VERSION ""

NS_ :

BS_:

BU_: VCU WheelSpeedSensor MotorController TempSensors BMS IMU

BO_ 256 WheelSpeed: 8 WheelSpeedSensor
 SG_ Speed_kmh : 0|16@1+ (0.1,0) [0|300] "km/h" VCU

BO_ 257 MotorRPM: 8 MotorController
 SG_ Motor_RPM : 0|16@1+ (1,0) [0|20000] "rpm" VCU

BO_ 258 MotorTemp: 8 TempSensors
 SG_ Motor_Temp_C : 0|16@1- (0.1,0) [-40|200] "degC" VCU

BO_ 259 CoolantTemp: 8 TempSensors
 SG_ Coolant_In_C : 0|16@1- (0.1,0) [-40|150] "degC" VCU
 SG_ Coolant_Out_C : 16|16@1- (0.1,0) [-40|150] "degC" VCU

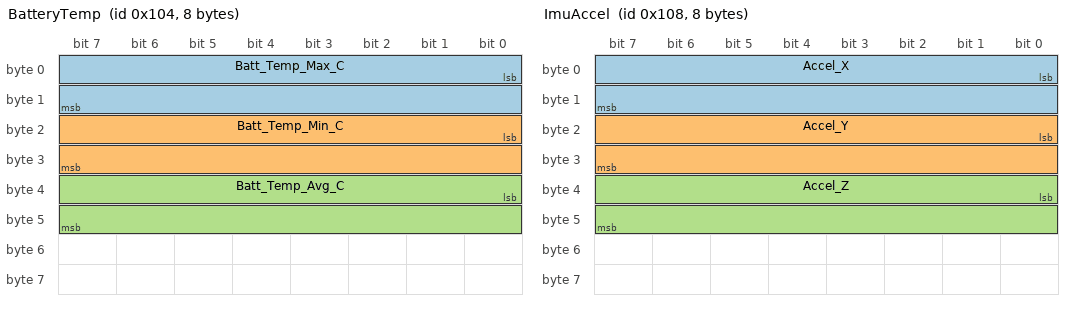
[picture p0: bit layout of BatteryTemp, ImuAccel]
BO_ 260 BatteryTemp: 8 BMS
 SG_ Batt_Temp_Max_C : 0|16@1- (0.1,0) [-40|100] "degC" VCU
 SG_ Batt_Temp_Min_C : 16|16@1- (0.1,0) [-40|100] "degC" VCU
 SG_ Batt_Temp_Avg_C : 32|16@1- (0.1,0) [-40|100] "degC" VCU

BO_ 261 BatteryVoltage: 8 BMS
 SG_ Pack_Voltage_V : 0|16@1+ (0.1,0) [0|500] "V" VCU

BO_ 262 BatteryCurrent: 8 BMS
 SG_ Pack_Current_A : 0|16@1- (0.1,0) [-500|500] "A" VCU

BO_ 263 InverterTemp: 8 MotorController
 SG_ Inverter_Temp_C : 0|16@1- (0.1,0) [-40|200] "degC" VCU

BO_ 264 ImuAccel: 8 IMU
 SG_ Accel_X : 0|16@1- (0.001,0) [-16|16] "g" VCU
 SG_ Accel_Y : 16|16@1- (0.001,0) [-16|16] "g" VCU
 SG_ Accel_Z : 32|16@1- (0.001,0) [-16|16] "g" VCU

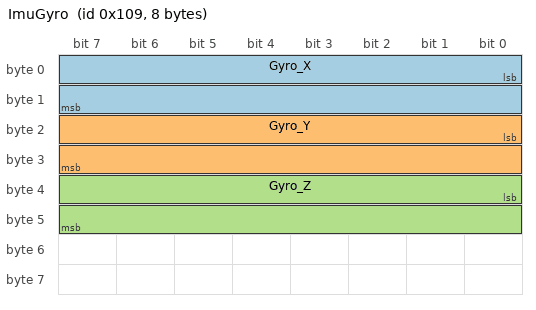
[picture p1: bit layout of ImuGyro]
BO_ 265 ImuGyro: 8 IMU
 SG_ Gyro_X : 0|16@1- (0.01,0) [-2000|2000] "deg/s" VCU
 SG_ Gyro_Y : 16|16@1- (0.01,0) [-2000|2000] "deg/s" VCU
 SG_ Gyro_Z : 32|16@1- (0.01,0) [-2000|2000] "deg/s" VCU

CM_ BU_ VCU "The vehicle control unit - listens to all nodes and makes decisions.";
CM_ BO_ 256 "Wheel speed sensor output. Used for speedometer and traction logic.";
CM_ BO_ 262 "Signed: positive = discharging (powering the motor), negative = charging (regen/charger).";
CM_ SG_ 264 Accel_X "Longitudinal acceleration (forward/back), in units of g (9.81 m/s^2).";

BA_DEF_ BO_ "GenMsgCycleTime" INT 0 10000;
BA_DEF_DEF_ "GenMsgCycleTime" 100;
BA_ "GenMsgCycleTime" BO_ 256 20;
BA_ "GenMsgCycleTime" BO_ 257 10;
BA_ "GenMsgCycleTime" BO_ 262 20;
BA_ "GenMsgCycleTime" BO_ 264 10;
BA_ "GenMsgCycleTime" BO_ 265 10;
